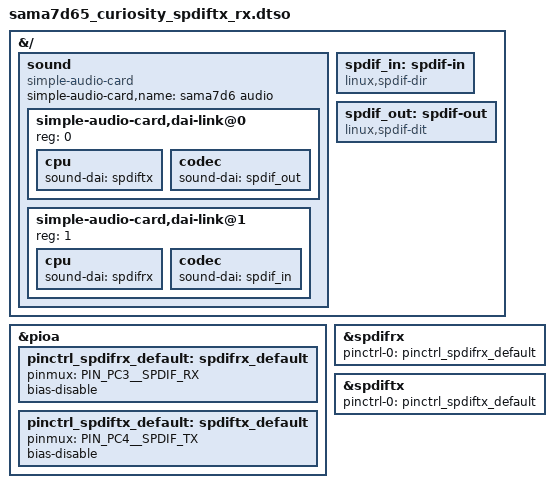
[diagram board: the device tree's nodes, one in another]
// SPDX-License-Identifier: (GPL-2.0+ OR MIT)
/*
 * Device Tree file for SAMA7D65-CURIOSITY board
 * overlay blob for SPDIF RX and TX Raspberry Pi Connector Pin 11 and 13.
 *
 * Copyright (C) 2026 Microchip Technology Inc. and its subsidiaries
 * Author: Joemel John Diente <JoemelJohn.Diente@microchip.com>
 * Status: Working but not verified. Shows on "dmesg | grep spdifrx && aplay -l"
 * 
 * SAMA7D65 Curiosity Raspberry Pi Connector Pinout
 * PC3 SPDIF RX - Pi Hat Connector Pin 11
 * PC4 SPDIF TX - Pi Hat Connector Pin 13
 *
 */

/dts-v1/;
/plugin/;
#include "sama7d65-pinfunc.h"
#include <dt-bindings/clock/at91.h>
#include <dt-bindings/mfd/atmel-flexcom.h>

&{/} {
	sound: sound {
		compatible = "simple-audio-card";
		simple-audio-card,name = "sama7d6 audio";
		#address-cells = <1>;
		#size-cells = <0>;
		simple-audio-card,dai-link@0 {
			reg = <0>;
			cpu {
				sound-dai = <&spdiftx>;
			};
			codec {
				sound-dai = <&spdif_out>;
			};
		};
		simple-audio-card,dai-link@1 {
			reg = <1>;
			cpu {
				sound-dai = <&spdifrx>;
			};
			codec {
				sound-dai = <&spdif_in>;
			};
		};
	};

	spdif_in: spdif-in {
		#sound-dai-cells = <0>;
		compatible = "linux,spdif-dir";
	};

	spdif_out: spdif-out {
		#sound-dai-cells = <0>;
		compatible = "linux,spdif-dit";
	};
};

&pioa {
	pinctrl_spdifrx_default: spdifrx_default {
		pinmux = <PIN_PC3__SPDIF_RX>;
		bias-disable;
	};

	pinctrl_spdiftx_default: spdiftx_default {
		pinmux = <PIN_PC4__SPDIF_TX>;
		bias-disable;
	};
};

&spdifrx {
	pinctrl-names = "default";
	pinctrl-0 = <&pinctrl_spdifrx_default>;
	status = "okay";
};

&spdiftx {
	pinctrl-names = "default";
	pinctrl-0 = <&pinctrl_spdiftx_default>;
	status = "okay";
};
